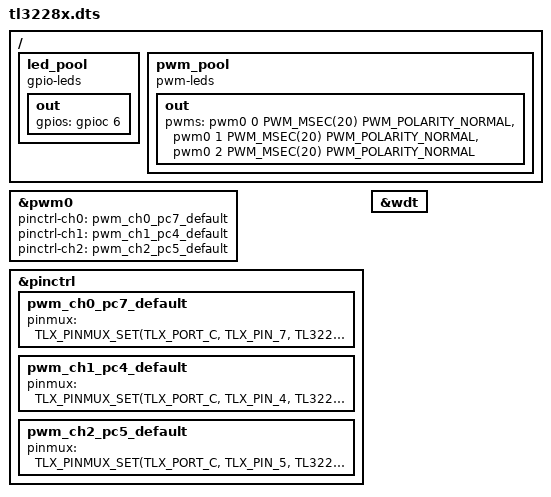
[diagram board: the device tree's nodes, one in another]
/*
 * Copyright (c) 2025 Telink Semiconductor
 *
 * SPDX-License-Identifier: Apache-2.0
 */

/dts-v1/;

#include "tl3228x-common.dtsi"

/ {
	led_pool {
		compatible = "gpio-leds";

		out {
			gpios = <&gpioc 6 GPIO_ACTIVE_HIGH>;
		};
	};

	pwm_pool {
		compatible = "pwm-leds";
		out {
			pwms = <&pwm0 0 PWM_MSEC(20) PWM_POLARITY_NORMAL>,
				<&pwm0 1 PWM_MSEC(20) PWM_POLARITY_NORMAL>,
				<&pwm0 2 PWM_MSEC(20) PWM_POLARITY_NORMAL>;
		};
	};
};

&pwm0 {
	/* On board RGB LEDs */
	pinctrl-ch0 = <&pwm_ch0_pc7_default>;
	pinctrl-ch1 = <&pwm_ch1_pc4_default>;
	pinctrl-ch2 = <&pwm_ch2_pc5_default>;
};

&pinctrl {
	pwm_ch0_pc7_default: pwm_ch0_pc7_default {
		pinmux = <TLX_PINMUX_SET(TLX_PORT_C, TLX_PIN_7, TL322X_FUNC_PWM0)>;
	};
	pwm_ch1_pc4_default: pwm_ch1_pc4_default {
		pinmux = <TLX_PINMUX_SET(TLX_PORT_C, TLX_PIN_4, TL322X_FUNC_PWM4)>;
	};
	pwm_ch2_pc5_default: pwm_ch2_pc5_default {
		pinmux = <TLX_PINMUX_SET(TLX_PORT_C, TLX_PIN_5, TL322X_FUNC_PWM8)>;
	};
};

&wdt {
	status = "okay";
};
